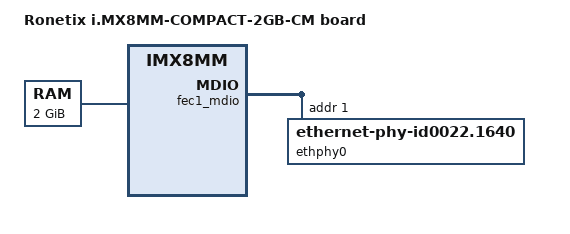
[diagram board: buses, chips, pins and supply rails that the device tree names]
// SPDX-License-Identifier: (GPL-2.0+ OR MIT)
/*
 * Copyright 2019 NXP
 * Copyright 2026 Ronetix GmbH
 */

/dts-v1/;

#include "imx8mm-compact-cm.dtsi"

/ {
	model = "Ronetix i.MX8MM-COMPACT-2GB-CM board";
	compatible = "ronetix,imx8mm-compact-2gb-cm", "fsl,imx8mm";

	memory@40000000 {
		device_type = "memory";
		reg = <0x0 0x40000000 0 0x80000000>;
	};
};

&fec1_mdio {
	/* KSZ9131RNX */
	ethphy0: ethernet-phy@1 {
		compatible = "ethernet-phy-id0022.1640",
			     "ethernet-phy-ieee802.3-c22";
		reg = <1>;
		rxc-skew-psec = <2400>;
		txc-skew-psec = <2400>;
		rxdv-skew-psec = <0>;
		txen-skew-psec = <0>;
		rxd0-skew-psec = <0>;
		rxd1-skew-psec = <0>;
		rxd2-skew-psec = <0>;
		rxd3-skew-psec = <0>;
		txd0-skew-psec = <0>;
		txd1-skew-psec = <0>;
		txd2-skew-psec = <0>;
		txd3-skew-psec = <0>;
	};
};
